AUTOSAR XML (schema 4-3-0)
package /ComponentTypes
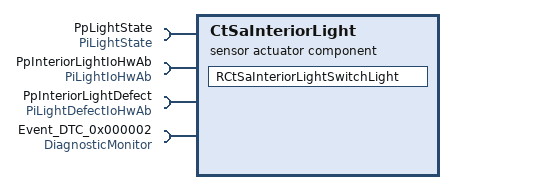
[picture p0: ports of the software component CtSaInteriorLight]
  sensor actuator sw component type CtSaInteriorLight
    4 x require port:
      PpLightState: nonqueued-receiver-com-spec{data-element=DeLightState, filter=data-filter-type=ALWAYS, init-value=constant-reference=CLightOff}, required-interface=PiLightState
      PpInteriorLightIoHwAb: client-com-spec=WriteChannel, required-interface=PiLightIoHwAb
      PpInteriorLightDefect: client-com-spec=ReadChannel, required-interface=PiLightDefectIoHwAb
      Event_DTC_0x000002: required-interface=DiagnosticMonitor
        required-com-specs:
          SetEventStatus
          ResetEventStatus
          ResetEventDebounceStatus
          GetEventUdsStatus
          GetEventStatus
          GetEventFailed
          GetEventTested
          GetDTCOfEvent
          GetFaultDetectionCounter
          GetEventFreezeFrameDataEx
          GetEventExtendedDataRecordEx
    behavior CtSaInteriorLight_InternalBehavior: data-type-mapping=DemoTypeMapping, supports-multiple-instantiation=true
      data received event DRT_RCtSaInteriorLightSwitchLight_PpLightState_DeLightState: start-on-event=RCtSaInteriorLightSwitchLight, data=PpLightState.DeLightState
      runnable RCtSaInteriorLightSwitchLight
        data-receive-point-by-arguments:
          access REC_PpLightState_DeLightState: accessed-variable=PpLightState.DeLightState
        sync call SC_PpLightIoHwAb_WriteChannel: operation=PpInteriorLightIoHwAb.WriteChannel
        sync call SC_PpInteriorLightDefect_ReadChannel: operation=PpInteriorLightDefect.ReadChannel
        sync call SC_Event_DTC_0x000002_SetEventStatus: operation=Event_DTC_0x000002.SetEventStatus
  swc implementation CtSaInteriorLight_Implementation: behavior=CtSaInteriorLight_InternalBehavior
